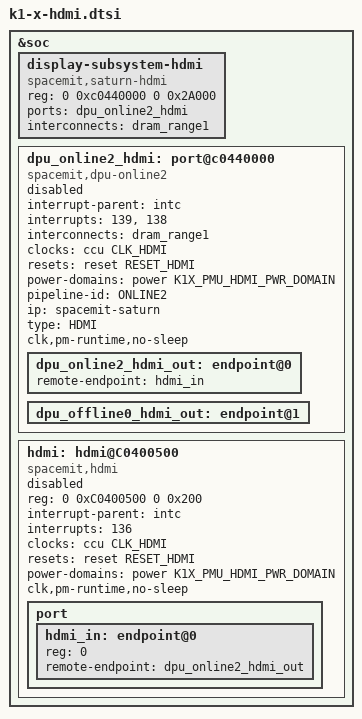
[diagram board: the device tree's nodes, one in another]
// SPDX-License-Identifier: (GPL-2.0 OR MIT)
/* Copyright (c) 2023 Spacemit, Inc */

&soc {
	display-subsystem-hdmi {
		compatible = "spacemit,saturn-hdmi";
		reg = <0 0xc0440000 0 0x2A000>;
		ports = <&dpu_online2_hdmi>;
		interconnects = <&dram_range1>;
		interconnect-names = "dma-mem";
	};

	dpu_online2_hdmi: port@c0440000 {
		compatible = "spacemit,dpu-online2";
		interrupt-parent = <&intc>;
		interrupts = <139>, <138>;
		interrupt-names = "ONLINE_IRQ", "OFFLINE_IRQ";
		interconnects = <&dram_range1>;
		interconnect-names = "dma-mem";
		clocks = <&ccu CLK_HDMI>;
		clock-names = "hmclk";
		resets = <&reset RESET_HDMI>;
		reset-names= "hdmi_reset";
		power-domains = <&power K1X_PMU_HDMI_PWR_DOMAIN>;
		pipeline-id = <ONLINE2>;
		ip = "spacemit-saturn";
		type = <HDMI>;
		clk,pm-runtime,no-sleep;
		status = "disabled";

		dpu_online2_hdmi_out: endpoint@0 {
			remote-endpoint = <&hdmi_in>;
		};

		dpu_offline0_hdmi_out: endpoint@1 {
			/* remote-endpoint = <&wb0_in>; */
		};
	};

	hdmi: hdmi@C0400500 {
		compatible = "spacemit,hdmi";
		reg = <0 0xC0400500 0 0x200>;
		interrupt-parent = <&intc>;
		interrupts = <136>;
		clocks = <&ccu CLK_HDMI>;
		clock-names = "hmclk";
		resets = <&reset RESET_HDMI>;
		reset-names= "hdmi_reset";
		power-domains = <&power K1X_PMU_HDMI_PWR_DOMAIN>;
		clk,pm-runtime,no-sleep;
		status = "disabled";

		port {
			#address-cells = <1>;
			#size-cells = <0>;
			hdmi_in: endpoint@0 {
				reg = <0>;
				remote-endpoint = <&dpu_online2_hdmi_out>;
			};
		};
	};
};
